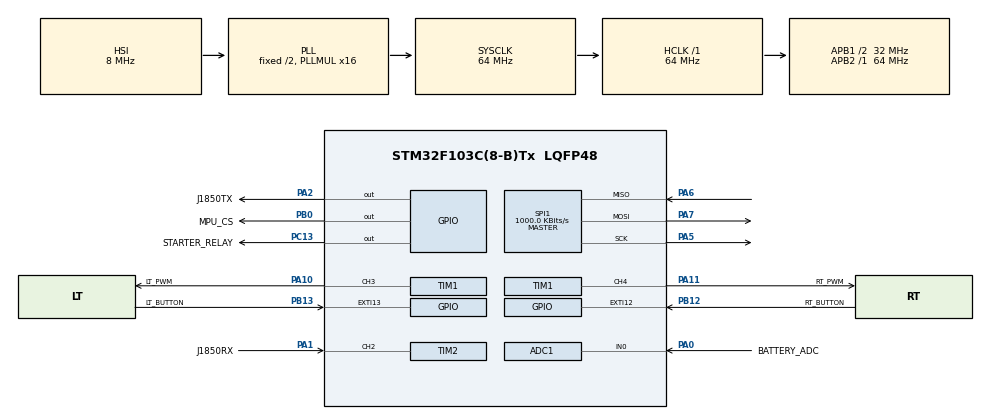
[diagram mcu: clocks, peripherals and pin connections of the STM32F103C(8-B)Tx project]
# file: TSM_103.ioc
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ADC1.Channel-28\#ChannelRegularConversion=ADC_CHANNEL_0
ADC1.Channel-29\#ChannelRegularConversion=ADC_CHANNEL_0
ADC1.Channel-30\#ChannelRegularConversion=ADC_CHANNEL_0
ADC1.Channel-31\#ChannelRegularConversion=ADC_CHANNEL_0
ADC1.Channel-32\#ChannelRegularConversion=ADC_CHANNEL_0
ADC1.Channel-33\#ChannelRegularConversion=ADC_CHANNEL_0
ADC1.Channel-34\#ChannelRegularConversion=ADC_CHANNEL_0
ADC1.Channel-35\#ChannelRegularConversion=ADC_CHANNEL_0
ADC1.Channel-36\#ChannelRegularConversion=ADC_CHANNEL_0
ADC1.Channel-37\#ChannelRegularConversion=ADC_CHANNEL_0
ADC1.Channel-38\#ChannelRegularConversion=ADC_CHANNEL_0
ADC1.Channel-39\#ChannelRegularConversion=ADC_CHANNEL_0
ADC1.Channel-40\#ChannelRegularConversion=ADC_CHANNEL_0
ADC1.Channel-41\#ChannelRegularConversion=ADC_CHANNEL_0
ADC1.Channel-42\#ChannelRegularConversion=ADC_CHANNEL_0
ADC1.Channel-43\#ChannelRegularConversion=ADC_CHANNEL_0
ADC1.ContinuousConvMode=ENABLE
ADC1.EnableRegularConversion=ENABLE
ADC1.Mode=__NULL
ADC1.NbrOfConversion=16
ADC1.NbrOfConversionFlag=1
ADC1.Rank-28\#ChannelRegularConversion=1
ADC1.Rank-29\#ChannelRegularConversion=2
ADC1.Rank-30\#ChannelRegularConversion=3
ADC1.Rank-31\#ChannelRegularConversion=4
ADC1.Rank-32\#ChannelRegularConversion=5
ADC1.Rank-33\#ChannelRegularConversion=6
ADC1.Rank-34\#ChannelRegularConversion=7
ADC1.Rank-35\#ChannelRegularConversion=8
ADC1.Rank-36\#ChannelRegularConversion=9
ADC1.Rank-37\#ChannelRegularConversion=10
ADC1.Rank-38\#ChannelRegularConversion=11
ADC1.Rank-39\#ChannelRegularConversion=12
ADC1.Rank-40\#ChannelRegularConversion=13
ADC1.Rank-41\#ChannelRegularConversion=14
ADC1.Rank-42\#ChannelRegularConversion=15
ADC1.Rank-43\#ChannelRegularConversion=16
ADC1.SamplingTime-28\#ChannelRegularConversion=ADC_SAMPLETIME_1CYCLE_5
ADC1.SamplingTime-29\#ChannelRegularConversion=ADC_SAMPLETIME_1CYCLE_5
ADC1.SamplingTime-30\#ChannelRegularConversion=ADC_SAMPLETIME_1CYCLE_5
ADC1.SamplingTime-31\#ChannelRegularConversion=ADC_SAMPLETIME_1CYCLE_5
ADC1.SamplingTime-32\#ChannelRegularConversion=ADC_SAMPLETIME_1CYCLE_5
ADC1.SamplingTime-33\#ChannelRegularConversion=ADC_SAMPLETIME_1CYCLE_5
ADC1.SamplingTime-34\#ChannelRegularConversion=ADC_SAMPLETIME_1CYCLE_5
ADC1.SamplingTime-35\#ChannelRegularConversion=ADC_SAMPLETIME_1CYCLE_5
ADC1.SamplingTime-36\#ChannelRegularConversion=ADC_SAMPLETIME_1CYCLE_5
ADC1.SamplingTime-37\#ChannelRegularConversion=ADC_SAMPLETIME_1CYCLE_5
ADC1.SamplingTime-38\#ChannelRegularConversion=ADC_SAMPLETIME_1CYCLE_5
ADC1.SamplingTime-39\#ChannelRegularConversion=ADC_SAMPLETIME_1CYCLE_5
ADC1.SamplingTime-40\#ChannelRegularConversion=ADC_SAMPLETIME_1CYCLE_5
ADC1.SamplingTime-41\#ChannelRegularConversion=ADC_SAMPLETIME_1CYCLE_5
ADC1.SamplingTime-42\#ChannelRegularConversion=ADC_SAMPLETIME_1CYCLE_5
ADC1.SamplingTime-43\#ChannelRegularConversion=ADC_SAMPLETIME_1CYCLE_5
ADC1.master=1
Dma.ADC1.0.Direction=DMA_PERIPH_TO_MEMORY
Dma.ADC1.0.Instance=DMA1_Channel1
Dma.ADC1.0.MemDataAlignment=DMA_MDATAALIGN_WORD
Dma.ADC1.0.MemInc=DMA_MINC_ENABLE
Dma.ADC1.0.Mode=DMA_NORMAL
Dma.ADC1.0.PeriphDataAlignment=DMA_PDATAALIGN_WORD
Dma.ADC1.0.PeriphInc=DMA_PINC_DISABLE
Dma.ADC1.0.Priority=DMA_PRIORITY_LOW
Dma.Request0=ADC1
Mcu.Family=STM32F1
Mcu.Name=STM32F103C(8-B)Tx
Mcu.Package=LQFP48
NVIC.ADC1_2_IRQn=true\:0\:0\:false\:false\:true\:true\:true\:true
NVIC.DMA1_Channel1_IRQn=true\:0\:0\:false\:false\:true\:false\:true\:true
NVIC.EXTI15_10_IRQn=true\:0\:0\:false\:false\:true\:true\:true\:true
NVIC.PriorityGroup=NVIC_PRIORITYGROUP_4
NVIC.TIM2_IRQn=true\:0\:0\:false\:false\:true\:true\:true\:true
NVIC.TIM3_IRQn=true\:0\:0\:false\:false\:true\:true\:true\:true
NVIC.TIM4_IRQn=true\:0\:0\:false\:false\:true\:true\:true\:true
PA0-WKUP.GPIO_Label=BATTERY_ADC
PA0-WKUP.GPIO_Mode=GPIO_MODE_ANALOG
PA0-WKUP.Signal=ADCx_IN0
PA1.GPIO_Label=J1850RX
PA1.Signal=S_TIM2_CH2
PA10.GPIO_Label=LT_PWM
PA10.Signal=S_TIM1_CH3
PA11.GPIO_Label=RT_PWM
PA11.Signal=S_TIM1_CH4
PA13.Mode=Serial_Wire
PA13.Signal=SYS_JTMS-SWDIO
PA14.Mode=Serial_Wire
PA14.Signal=SYS_JTCK-SWCLK
PA2.GPIO_Label=J1850TX
PA2.GPIO_PuPd=GPIO_PULLDOWN
PA2.Signal=GPIO_Output
PA5.Mode=Full_Duplex_Master
PA5.Signal=SPI1_SCK
PA6.Mode=Full_Duplex_Master
PA6.Signal=SPI1_MISO
PA7.Mode=Full_Duplex_Master
PA7.Signal=SPI1_MOSI
PB0.GPIO_Label=MPU_CS
PB0.GPIO_PuPd=GPIO_NOPULL
PB0.GPIO_Speed=GPIO_SPEED_FREQ_HIGH
PB0.PinState=GPIO_PIN_RESET
PB0.Signal=GPIO_Output
PB12.GPIO_Label=RT_BUTTON
PB12.GPIO_ModeDefaultEXTI=GPIO_MODE_IT_FALLING
PB12.Signal=GPXTI12
PB13.GPIO_Label=LT_BUTTON
PB13.GPIO_ModeDefaultEXTI=GPIO_MODE_IT_FALLING
PB13.Signal=GPXTI13
PC13-TAMPER-RTC.GPIO_Label=STARTER_RELAY
PC13-TAMPER-RTC.Signal=GPIO_Output
ProjectManager.HeapSize=0x200
ProjectManager.StackSize=0x400
ProjectManager.TargetToolchain=Makefile
RCC.ADCPresc=RCC_ADCPCLK2_DIV8
RCC.AHBFreq_Value=64000000
RCC.APB1CLKDivider=RCC_HCLK_DIV2
RCC.APB1Freq_Value=32000000
RCC.APB1TimFreq_Value=64000000
RCC.APB2Freq_Value=64000000
RCC.APB2TimFreq_Value=64000000
RCC.HCLKFreq_Value=64000000
RCC.PLLMUL=RCC_PLL_MUL16
RCC.SYSCLKFreq_VALUE=64000000
RCC.SYSCLKSource=RCC_SYSCLKSOURCE_PLLCLK
RCC.TimSys_Div=SYSTICK_CLKSOURCE_HCLK_DIV8
RCC.USBFreq_Value=64000000
SH.ADCx_IN0.0=ADC1_IN0,IN0
SH.ADCx_IN0.1=ADC2_IN0
SH.S_TIM1_CH3.0=TIM1_CH3,PWM Generation3 CH3
SH.S_TIM1_CH4.0=TIM1_CH4,PWM Generation4 CH4
SH.S_TIM2_CH2.0=TIM2_CH2,Input_Capture2_from_TI2
SPI1.BaudRatePrescaler=SPI_BAUDRATEPRESCALER_64
SPI1.CalculateBaudRate=1000.0 KBits/s
SPI1.Direction=SPI_DIRECTION_2LINES
SPI1.Mode=SPI_MODE_MASTER
SPI1.VirtualType=VM_MASTER
TIM1.AutoReloadPreload=TIM_AUTORELOAD_PRELOAD_ENABLE
TIM1.Channel-PWM\ Generation3\ CH3=TIM_CHANNEL_3
TIM1.Channel-PWM\ Generation4\ CH4=TIM_CHANNEL_4
TIM1.OC4Preload_PWM=ENABLE
TIM1.OCFastMode_PWM-PWM\ Generation3\ CH3=TIM_OCFAST_ENABLE
TIM1.OCFastMode_PWM-PWM\ Generation4\ CH4=TIM_OCFAST_ENABLE
TIM1.OCMode_PWM-PWM\ Generation3\ CH3=TIM_OCMODE_PWM1
TIM1.OCPolarity_3=TIM_OCPOLARITY_HIGH
TIM1.OCPolarity_4=TIM_OCPOLARITY_HIGH
TIM1.Period=100
TIM1.Prescaler=1000
TIM1.Pulse-PWM\ Generation3\ CH3=0
TIM1.Pulse-PWM\ Generation4\ CH4=0
TIM2.Channel-Input_Capture2_from_TI2=TIM_CHANNEL_2
TIM2.ClockDivision=TIM_CLOCKDIVISION_DIV1
TIM2.Period=65535
TIM2.Prescaler=63
TIM3.AutoReloadPreload=TIM_AUTORELOAD_PRELOAD_DISABLE
TIM3.CounterMode=TIM_COUNTERMODE_UP
TIM3.Period=247
TIM3.Prescaler=63
TIM4.Period=703
TIM4.Prescaler=9999
VP_CRC_VS_CRC.Mode=CRC_Activate
VP_TIM1_VS_ClockSourceINT.Mode=Internal
VP_TIM2_VS_ClockSourceINT.Mode=Internal
VP_TIM3_VS_ClockSourceINT.Mode=Internal
VP_TIM4_VS_ClockSourceINT.Mode=Internal
board=custom

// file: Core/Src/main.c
/* USER CODE BEGIN Header */
/**
 ******************************************************************************
 * @file           : main.c
 * @brief          : Main program body
 ******************************************************************************
 * @attention
 *
 * <h2><center>&copy; Copyright (c) 2021 STMicroelectronics.
 * All rights reserved.</center></h2>
 *
 * This software component is licensed by ST under BSD 3-Clause license,
 * the "License"; You may not use this file except in compliance with the
 * License. You may obtain a copy of the License at:
 *                        opensource.org/licenses/BSD-3-Clause
 *
 ******************************************************************************
 */
/* USER CODE END Header */
#include "main.h"
#include "adc.h"
#include "crc.h"
#include "dma.h"
#include "spi.h"
#include "tim.h"
#include "gpio.h"

/* USER CODE BEGIN Includes */
#include "dwtdelay.h"

/* USER CODE END Includes */

void SystemClock_Config(void);
/* USER CODE BEGIN PFP */
void tsmRunApp();
/* USER CODE END PFP */

int main(void)
{

  /* MCU Configuration--------------------------------------------------------*/

  /* Reset of all peripherals, Initializes the Flash interface and the Systick. */
  HAL_Init();

  /* Configure the system clock */
  SystemClock_Config();

  /* Initialize all configured peripherals */
  MX_GPIO_Init();
  MX_DMA_Init();
  MX_ADC1_Init();
  MX_TIM1_Init();
  MX_TIM3_Init();
  MX_TIM4_Init();
  MX_TIM2_Init();
  MX_CRC_Init();
  MX_SPI1_Init();
  /* USER CODE BEGIN 2 */
  DWT_Init();
  tsmRunApp();
  /* USER CODE END 2 */

  /* Infinite loop */
  while (1)
  {

  }
}

void SystemClock_Config(void)
{
  RCC_OscInitTypeDef RCC_OscInitStruct = {0};
  RCC_ClkInitTypeDef RCC_ClkInitStruct = {0};
  RCC_PeriphCLKInitTypeDef PeriphClkInit = {0};

  /** Initializes the RCC Oscillators according to the specified parameters
  * in the RCC_OscInitTypeDef structure.
  */
  RCC_OscInitStruct.OscillatorType = RCC_OSCILLATORTYPE_HSI;
  RCC_OscInitStruct.HSIState = RCC_HSI_ON;
  RCC_OscInitStruct.HSICalibrationValue = RCC_HSICALIBRATION_DEFAULT;
  RCC_OscInitStruct.PLL.PLLState = RCC_PLL_ON;
  RCC_OscInitStruct.PLL.PLLSource = RCC_PLLSOURCE_HSI_DIV2;
  RCC_OscInitStruct.PLL.PLLMUL = RCC_PLL_MUL16;
  if (HAL_RCC_OscConfig(&RCC_OscInitStruct) != HAL_OK)
  {
    Error_Handler();
  }

  /** Initializes the CPU, AHB and APB buses clocks
  */
  RCC_ClkInitStruct.ClockType = RCC_CLOCKTYPE_HCLK|RCC_CLOCKTYPE_SYSCLK
                              |RCC_CLOCKTYPE_PCLK1|RCC_CLOCKTYPE_PCLK2;
  RCC_ClkInitStruct.SYSCLKSource = RCC_SYSCLKSOURCE_PLLCLK;
  RCC_ClkInitStruct.AHBCLKDivider = RCC_SYSCLK_DIV1;
  RCC_ClkInitStruct.APB1CLKDivider = RCC_HCLK_DIV2;
  RCC_ClkInitStruct.APB2CLKDivider = RCC_HCLK_DIV1;

  if (HAL_RCC_ClockConfig(&RCC_ClkInitStruct, FLASH_LATENCY_2) != HAL_OK)
  {
    Error_Handler();
  }
  PeriphClkInit.PeriphClockSelection = RCC_PERIPHCLK_ADC;
  PeriphClkInit.AdcClockSelection = RCC_ADCPCLK2_DIV8;
  if (HAL_RCCEx_PeriphCLKConfig(&PeriphClkInit) != HAL_OK)
  {
    Error_Handler();
  }
}

void Error_Handler(void)
{
  __disable_irq();
  while (1)
  {
  }
}
